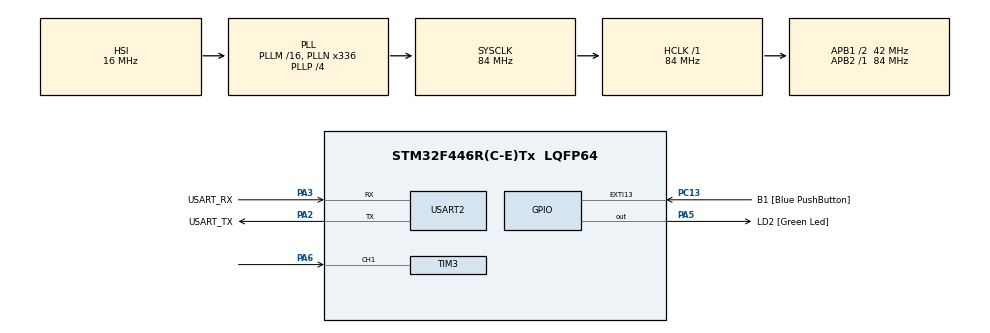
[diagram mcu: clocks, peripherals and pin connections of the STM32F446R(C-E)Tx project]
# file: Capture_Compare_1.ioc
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Dma.Request0=TIM1_UP
Dma.TIM1_UP.0.Direction=DMA_MEMORY_TO_PERIPH
Dma.TIM1_UP.0.FIFOMode=DMA_FIFOMODE_DISABLE
Dma.TIM1_UP.0.Instance=DMA2_Stream5
Dma.TIM1_UP.0.MemDataAlignment=DMA_MDATAALIGN_WORD
Dma.TIM1_UP.0.MemInc=DMA_MINC_ENABLE
Dma.TIM1_UP.0.Mode=DMA_CIRCULAR
Dma.TIM1_UP.0.PeriphDataAlignment=DMA_PDATAALIGN_WORD
Dma.TIM1_UP.0.PeriphInc=DMA_PINC_DISABLE
Dma.TIM1_UP.0.Priority=DMA_PRIORITY_LOW
Mcu.Family=STM32F4
Mcu.Name=STM32F446R(C-E)Tx
Mcu.Package=LQFP64
NVIC.DMA2_Stream5_IRQn=true\:0\:0\:false\:false\:true\:false\:true\:true
NVIC.PriorityGroup=NVIC_PRIORITYGROUP_0
NVIC.TIM3_IRQn=true\:0\:0\:false\:false\:true\:true\:true\:true
PA13.GPIO_Label=TMS
PA13.Signal=SYS_JTMS-SWDIO
PA14.GPIO_Label=TCK
PA14.Signal=SYS_JTCK-SWCLK
PA2.GPIO_Label=USART_TX
PA2.Mode=Asynchronous
PA2.Signal=USART2_TX
PA3.GPIO_Label=USART_RX
PA3.Mode=Asynchronous
PA3.Signal=USART2_RX
PA5.GPIO_Label=LD2 [Green Led]
PA5.Signal=GPIO_Output
PA6.Signal=S_TIM3_CH1
PB3.GPIO_Label=SWO
PB3.Signal=SYS_JTDO-SWO
PC13.GPIO_Label=B1 [Blue PushButton]
PC13.GPIO_ModeDefaultEXTI=GPIO_MODE_IT_FALLING
PC13.Signal=GPXTI13
PC14-OSC32_IN.Signal=RCC_OSC32_IN
PC15-OSC32_OUT.Signal=RCC_OSC32_OUT
PH0-OSC_IN.Signal=RCC_OSC_IN
PH1-OSC_OUT.Signal=RCC_OSC_OUT
ProjectManager.HeapSize=0x200
ProjectManager.StackSize=0x400
ProjectManager.TargetToolchain=STM32CubeIDE
RCC.AHBFreq_Value=84000000
RCC.APB1CLKDivider=RCC_HCLK_DIV2
RCC.APB1Freq_Value=42000000
RCC.APB1TimFreq_Value=84000000
RCC.APB2Freq_Value=84000000
RCC.APB2TimFreq_Value=84000000
RCC.CortexFreq_Value=84000000
RCC.FLatency-AdvancedSettings=FLASH_LATENCY_2
RCC.HCLKFreq_Value=84000000
RCC.HSE_VALUE=8000000
RCC.HSI_VALUE=16000000
RCC.LSE_VALUE=32768
RCC.PLLN=336
RCC.PLLP=RCC_PLLP_DIV4
RCC.SYSCLKFreq_VALUE=84000000
RCC.SYSCLKSource=RCC_SYSCLKSOURCE_PLLCLK
RCC.USBFreq_Value=168000000
RCC.VCOOutputFreq_Value=336000000
SH.S_TIM3_CH1.0=TIM3_CH1,Input_Capture1_from_TI1
TIM1.Period=999
TIM1.Prescaler=4199
TIM3.Channel-Input_Capture1_from_TI1=TIM_CHANNEL_1
TIM3.Period=3999
TIM3.Prescaler=4199
USART2.VirtualMode=VM_ASYNC
VP_TIM1_VS_ClockSourceINT.Mode=Internal
VP_TIM3_VS_ClockSourceINT.Mode=Internal
board=NUCLEO-F446RE

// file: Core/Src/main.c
/* USER CODE BEGIN Header */
/**
  ******************************************************************************
  * @file           : main.c
  * @brief          : Main program body
  ******************************************************************************
  * @attention
  *
  * Copyright (c) 2026 STMicroelectronics.
  * All rights reserved.
  *
  * This software is licensed under terms that can be found in the LICENSE file
  * in the root directory of this software component.
  * If no LICENSE file comes with this software, it is provided AS-IS.
  *
  ******************************************************************************
  */
/* USER CODE END Header */
#include "main.h"
#include "string.h"
#include "stdio.h"

TIM_HandleTypeDef htim1;
TIM_HandleTypeDef htim3;
DMA_HandleTypeDef hdma_tim1_up;

UART_HandleTypeDef huart2;

void SystemClock_Config(void);
static void MX_GPIO_Init(void);
static void MX_DMA_Init(void);
static void MX_TIM3_Init(void);
static void MX_USART2_UART_Init(void);
static void MX_TIM1_Init(void);

volatile uint16_t capture[2] = {0,0};
volatile uint8_t state = 0;
volatile uint16_t elapsed = 0;
int main(void)
{

  /* MCU Configuration--------------------------------------------------------*/

  /* Reset of all peripherals, Initializes the Flash interface and the Systick. */
  HAL_Init();

  /* Configure the system clock */
  SystemClock_Config();

  /* Initialize all configured peripherals */
  MX_GPIO_Init();
  MX_DMA_Init();
  MX_TIM3_Init();
  MX_USART2_UART_Init();
  MX_TIM1_Init();
  /* USER CODE BEGIN 2 */
  uint32_t data[] = {(uint32_t)GPIO_PIN_5, (uint32_t)(GPIO_PIN_5 << 16)};

  HAL_TIM_Base_Start(&htim1);

  HAL_DMA_Start(&hdma_tim1_up, (uint32_t)data, (uint32_t)&GPIOA->BSRR, 2);
  __HAL_TIM_ENABLE_DMA(&htim1, TIM_DMA_UPDATE);

  HAL_TIM_Base_Start_IT(&htim3);
  HAL_TIM_IC_Start_IT(&htim3, TIM_CHANNEL_1);

  /* USER CODE END 2 */

  /* Infinite loop */
  while (1)
  {

	  if(state != 0)
	  	  {
	  		  if(state == 1)
	  		  	  {
	  		  		  char* trans = "\x1B[1;1H""\x1B[2J"
	  		  				  "We're in calculation:\r\n";
	  		  		  char cap1[30];
	  		  		  HAL_UART_Transmit(&huart2, (uint8_t*)trans, strlen(trans), HAL_MAX_DELAY);// notify
	  		  		  //Receive result from capture 0
	  		  		  snprintf(cap1, sizeof(cap1),"Capture 1: %d\r\n", capture[0]);
	  		  		  //Read capture 0 value
	  		  		  HAL_UART_Transmit(&huart2,(uint8_t*)cap1, strlen(cap1), HAL_MAX_DELAY );
	  		  	  }
	  		   else if(state == 2)
	  		   {
	  			  char cap2[30];
	  			  //Receive result from capture 1
	  			  snprintf(cap2, sizeof(cap2),"Capture 2: %d\r\n", capture[1]);
	  			  //Read capture 1 value
	  			  HAL_UART_Transmit(&huart2,(uint8_t*)cap2, strlen(cap2), HAL_MAX_DELAY );

	  			  uint32_t diff = 0;

	  			 diff = capture[1] - capture[0];
	  			  //Read the period switch light
	  			  double freq = 0.0;
	  			  char result[30];
	  			  freq = (double)(HAL_RCC_GetHCLKFreq()/(htim3.Instance->PSC + 1)) / diff ;
	  			  snprintf(result, sizeof(result), "The frequency: %.2lfHz\r\n", freq);
	  			  HAL_UART_Transmit(&huart2, (uint8_t*)result, strlen(result), HAL_MAX_DELAY);

	  			  HAL_TIM_IC_Stop_IT(&htim3, TIM_CHANNEL_1);
	  			  break;
	  		   }

	  	  }

  }
}

void SystemClock_Config(void)
{
  RCC_OscInitTypeDef RCC_OscInitStruct = {0};
  RCC_ClkInitTypeDef RCC_ClkInitStruct = {0};

  /** Configure the main internal regulator output voltage
  */
  __HAL_RCC_PWR_CLK_ENABLE();
  __HAL_PWR_VOLTAGESCALING_CONFIG(PWR_REGULATOR_VOLTAGE_SCALE3);

  /** Initializes the RCC Oscillators according to the specified parameters
  * in the RCC_OscInitTypeDef structure.
  */
  RCC_OscInitStruct.OscillatorType = RCC_OSCILLATORTYPE_HSI;
  RCC_OscInitStruct.HSIState = RCC_HSI_ON;
  RCC_OscInitStruct.HSICalibrationValue = RCC_HSICALIBRATION_DEFAULT;
  RCC_OscInitStruct.PLL.PLLState = RCC_PLL_ON;
  RCC_OscInitStruct.PLL.PLLSource = RCC_PLLSOURCE_HSI;
  RCC_OscInitStruct.PLL.PLLM = 16;
  RCC_OscInitStruct.PLL.PLLN = 336;
  RCC_OscInitStruct.PLL.PLLP = RCC_PLLP_DIV4;
  RCC_OscInitStruct.PLL.PLLQ = 2;
  RCC_OscInitStruct.PLL.PLLR = 2;
  if (HAL_RCC_OscConfig(&RCC_OscInitStruct) != HAL_OK)
  {
    Error_Handler();
  }

  /** Initializes the CPU, AHB and APB buses clocks
  */
  RCC_ClkInitStruct.ClockType = RCC_CLOCKTYPE_HCLK|RCC_CLOCKTYPE_SYSCLK
                              |RCC_CLOCKTYPE_PCLK1|RCC_CLOCKTYPE_PCLK2;
  RCC_ClkInitStruct.SYSCLKSource = RCC_SYSCLKSOURCE_PLLCLK;
  RCC_ClkInitStruct.AHBCLKDivider = RCC_SYSCLK_DIV1;
  RCC_ClkInitStruct.APB1CLKDivider = RCC_HCLK_DIV2;
  RCC_ClkInitStruct.APB2CLKDivider = RCC_HCLK_DIV1;

  if (HAL_RCC_ClockConfig(&RCC_ClkInitStruct, FLASH_LATENCY_2) != HAL_OK)
  {
    Error_Handler();
  }
}

static void MX_TIM1_Init(void)
{

  TIM_ClockConfigTypeDef sClockSourceConfig = {0};
  TIM_MasterConfigTypeDef sMasterConfig = {0};

  htim1.Instance = TIM1;
  htim1.Init.Prescaler = 4199;
  htim1.Init.CounterMode = TIM_COUNTERMODE_UP;
  htim1.Init.Period = 99;
  htim1.Init.ClockDivision = TIM_CLOCKDIVISION_DIV1;
  htim1.Init.RepetitionCounter = 0;
  htim1.Init.AutoReloadPreload = TIM_AUTORELOAD_PRELOAD_DISABLE;
  if (HAL_TIM_Base_Init(&htim1) != HAL_OK)
  {
    Error_Handler();
  }
  sClockSourceConfig.ClockSource = TIM_CLOCKSOURCE_INTERNAL;
  if (HAL_TIM_ConfigClockSource(&htim1, &sClockSourceConfig) != HAL_OK)
  {
    Error_Handler();
  }
  sMasterConfig.MasterOutputTrigger = TIM_TRGO_RESET;
  sMasterConfig.MasterSlaveMode = TIM_MASTERSLAVEMODE_DISABLE;
  if (HAL_TIMEx_MasterConfigSynchronization(&htim1, &sMasterConfig) != HAL_OK)
  {
    Error_Handler();
  }

}

static void MX_TIM3_Init(void)
{

  TIM_ClockConfigTypeDef sClockSourceConfig = {0};
  TIM_MasterConfigTypeDef sMasterConfig = {0};
  TIM_IC_InitTypeDef sConfigIC = {0};

  htim3.Instance = TIM3;
  htim3.Init.Prescaler = 4199;
  htim3.Init.CounterMode = TIM_COUNTERMODE_UP;
  htim3.Init.Period = 999;
  htim3.Init.ClockDivision = TIM_CLOCKDIVISION_DIV1;
  htim3.Init.AutoReloadPreload = TIM_AUTORELOAD_PRELOAD_DISABLE;
  if (HAL_TIM_Base_Init(&htim3) != HAL_OK)
  {
    Error_Handler();
  }
  sClockSourceConfig.ClockSource = TIM_CLOCKSOURCE_INTERNAL;
  if (HAL_TIM_ConfigClockSource(&htim3, &sClockSourceConfig) != HAL_OK)
  {
    Error_Handler();
  }
  if (HAL_TIM_IC_Init(&htim3) != HAL_OK)
  {
    Error_Handler();
  }
  sMasterConfig.MasterOutputTrigger = TIM_TRGO_RESET;
  sMasterConfig.MasterSlaveMode = TIM_MASTERSLAVEMODE_DISABLE;
  if (HAL_TIMEx_MasterConfigSynchronization(&htim3, &sMasterConfig) != HAL_OK)
  {
    Error_Handler();
  }
  sConfigIC.ICPolarity = TIM_INPUTCHANNELPOLARITY_RISING;
  sConfigIC.ICSelection = TIM_ICSELECTION_DIRECTTI;
  sConfigIC.ICPrescaler = TIM_ICPSC_DIV1;
  sConfigIC.ICFilter = 0;
  if (HAL_TIM_IC_ConfigChannel(&htim3, &sConfigIC, TIM_CHANNEL_1) != HAL_OK)
  {
    Error_Handler();
  }

}

static void MX_USART2_UART_Init(void)
{

  huart2.Instance = USART2;
  huart2.Init.BaudRate = 115200;
  huart2.Init.WordLength = UART_WORDLENGTH_8B;
  huart2.Init.StopBits = UART_STOPBITS_1;
  huart2.Init.Parity = UART_PARITY_NONE;
  huart2.Init.Mode = UART_MODE_TX_RX;
  huart2.Init.HwFlowCtl = UART_HWCONTROL_NONE;
  huart2.Init.OverSampling = UART_OVERSAMPLING_16;
  if (HAL_UART_Init(&huart2) != HAL_OK)
  {
    Error_Handler();
  }

}

static void MX_DMA_Init(void)
{

  /* DMA controller clock enable */
  __HAL_RCC_DMA2_CLK_ENABLE();

  /* DMA interrupt init */
  /* DMA2_Stream5_IRQn interrupt configuration */
  HAL_NVIC_SetPriority(DMA2_Stream5_IRQn, 0, 0);
  HAL_NVIC_EnableIRQ(DMA2_Stream5_IRQn);

}

static void MX_GPIO_Init(void)
{
  GPIO_InitTypeDef GPIO_InitStruct = {0};

  /* GPIO Ports Clock Enable */
  __HAL_RCC_GPIOC_CLK_ENABLE();
  __HAL_RCC_GPIOH_CLK_ENABLE();
  __HAL_RCC_GPIOA_CLK_ENABLE();
  __HAL_RCC_GPIOB_CLK_ENABLE();

  /*Configure GPIO pin Output Level */
  HAL_GPIO_WritePin(LD2_GPIO_Port, LD2_Pin, GPIO_PIN_RESET);

  /*Configure GPIO pin : B1_Pin */
  GPIO_InitStruct.Pin = B1_Pin;
  GPIO_InitStruct.Mode = GPIO_MODE_IT_FALLING;
  GPIO_InitStruct.Pull = GPIO_NOPULL;
  HAL_GPIO_Init(B1_GPIO_Port, &GPIO_InitStruct);

  /*Configure GPIO pin : LD2_Pin */
  GPIO_InitStruct.Pin = LD2_Pin;
  GPIO_InitStruct.Mode = GPIO_MODE_OUTPUT_PP;
  GPIO_InitStruct.Pull = GPIO_NOPULL;
  GPIO_InitStruct.Speed = GPIO_SPEED_FREQ_LOW;
  HAL_GPIO_Init(LD2_GPIO_Port, &GPIO_InitStruct);

}

void Error_Handler(void)
{
  __disable_irq();
  while (1)
  {
  }
}
